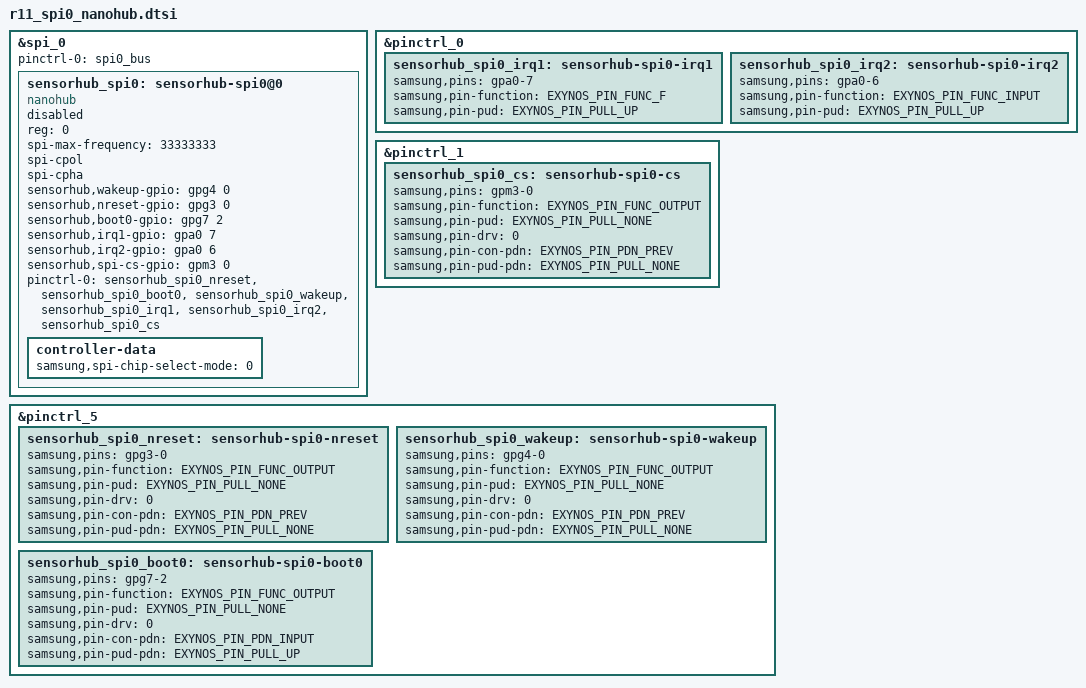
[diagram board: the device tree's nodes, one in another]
/*
 * Device Tree config for nanohub
 */

#include <dt-bindings/pinctrl/samsung.h>

&spi_0 {
	#address-cells = <1>;
	#size-cells = <0>;
	status = "ok";
	pinctrl-names = "default";
	pinctrl-0 = <&spi0_bus>;

	sensorhub_spi0: sensorhub-spi0@0 {
		compatible = "nanohub";
		reg = <0>;
		spi-max-frequency = <33333333>;
		spi-cpol;
		spi-cpha;
		sensorhub,wakeup-gpio = <&gpg4 0 0>;
		sensorhub,nreset-gpio = <&gpg3 0 0>;
		sensorhub,boot0-gpio = <&gpg7 2 0>;
		sensorhub,irq1-gpio = <&gpa0 7 0>;
		sensorhub,irq2-gpio = <&gpa0 6 0>;
		sensorhub,spi-cs-gpio = <&gpm3 0 0>;
		pinctrl-names = "default";
		pinctrl-0 = <&sensorhub_spi0_nreset &sensorhub_spi0_boot0 &sensorhub_spi0_wakeup &sensorhub_spi0_irq1 &sensorhub_spi0_irq2 &sensorhub_spi0_cs>;
		status = "disabled";

		controller-data {
			samsung,spi-chip-select-mode = <0>;
		};
	};
};

&pinctrl_0 {
	sensorhub_spi0_irq1: sensorhub-spi0-irq1 {
		samsung,pins = "gpa0-7";
		samsung,pin-function = <EXYNOS_PIN_FUNC_F>;
		samsung,pin-pud = <EXYNOS_PIN_PULL_UP>;
	};
	sensorhub_spi0_irq2: sensorhub-spi0-irq2 {
		samsung,pins = "gpa0-6";
		samsung,pin-function = <EXYNOS_PIN_FUNC_INPUT>;
		samsung,pin-pud = <EXYNOS_PIN_PULL_UP>;
	};
};

&pinctrl_1 {
	sensorhub_spi0_cs: sensorhub-spi0-cs {
		samsung,pins = "gpm3-0";
		samsung,pin-function = <EXYNOS_PIN_FUNC_OUTPUT>;
		samsung,pin-pud = <EXYNOS_PIN_PULL_NONE>;
		samsung,pin-drv = <0>;  /* LVL1 DRV */
		samsung,pin-con-pdn = <EXYNOS_PIN_PDN_PREV>;
		samsung,pin-pud-pdn = <EXYNOS_PIN_PULL_NONE>;
	};
};

&pinctrl_5 {
	sensorhub_spi0_nreset: sensorhub-spi0-nreset {
		samsung,pins = "gpg3-0";
		samsung,pin-function = <EXYNOS_PIN_FUNC_OUTPUT>;
		samsung,pin-pud = <EXYNOS_PIN_PULL_NONE>;
		samsung,pin-drv = <0>;	/* LVL1 DRV */
		samsung,pin-con-pdn = <EXYNOS_PIN_PDN_PREV>;
		samsung,pin-pud-pdn = <EXYNOS_PIN_PULL_NONE>;
	};
	sensorhub_spi0_wakeup: sensorhub-spi0-wakeup {
		samsung,pins = "gpg4-0";
		samsung,pin-function = <EXYNOS_PIN_FUNC_OUTPUT>;
		samsung,pin-pud = <EXYNOS_PIN_PULL_NONE>;
		samsung,pin-drv = <0>;	/* LVL1 DRV */
		samsung,pin-con-pdn = <EXYNOS_PIN_PDN_PREV>;
		samsung,pin-pud-pdn = <EXYNOS_PIN_PULL_NONE>;
	};
	sensorhub_spi0_boot0: sensorhub-spi0-boot0 {
		samsung,pins = "gpg7-2";
		samsung,pin-function = <EXYNOS_PIN_FUNC_OUTPUT>;
		samsung,pin-pud = <EXYNOS_PIN_PULL_NONE>;
		samsung,pin-drv = <0>;	/* LVL1 DRV */
		samsung,pin-con-pdn = <EXYNOS_PIN_PDN_INPUT>;
		samsung,pin-pud-pdn = <EXYNOS_PIN_PULL_UP>;
	};
};
